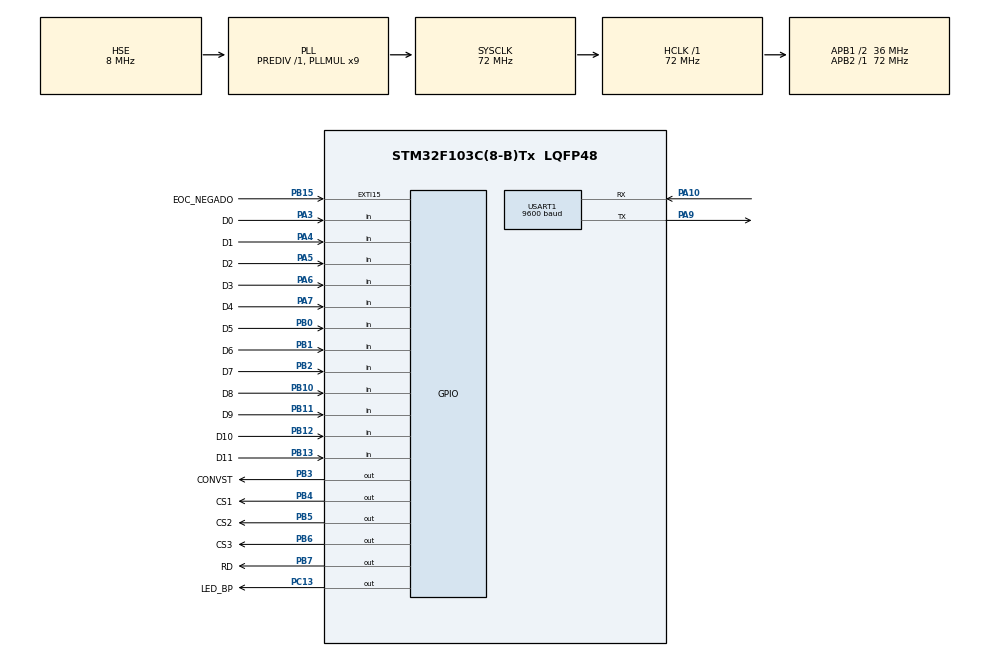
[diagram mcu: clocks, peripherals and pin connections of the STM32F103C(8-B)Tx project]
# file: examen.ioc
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Mcu.Family=STM32F1
Mcu.Name=STM32F103C(8-B)Tx
Mcu.Package=LQFP48
NVIC.PriorityGroup=NVIC_PRIORITYGROUP_4
PA10.Mode=Asynchronous
PA10.Signal=USART1_RX
PA13.Mode=Serial_Wire
PA13.Signal=SYS_JTMS-SWDIO
PA14.Mode=Serial_Wire
PA14.Signal=SYS_JTCK-SWCLK
PA3.GPIO_Label=D0
PA3.Signal=GPIO_Input
PA4.GPIO_Label=D1
PA4.Signal=GPIO_Input
PA5.GPIO_Label=D2
PA5.Signal=GPIO_Input
PA6.GPIO_Label=D3
PA6.Signal=GPIO_Input
PA7.GPIO_Label=D4
PA7.Signal=GPIO_Input
PA9.Mode=Asynchronous
PA9.Signal=USART1_TX
PB0.GPIO_Label=D5
PB0.Signal=GPIO_Input
PB1.GPIO_Label=D6
PB1.Signal=GPIO_Input
PB10.GPIO_Label=D8
PB10.Signal=GPIO_Input
PB11.GPIO_Label=D9
PB11.Signal=GPIO_Input
PB12.GPIO_Label=D10
PB12.Signal=GPIO_Input
PB13.GPIO_Label=D11
PB13.Signal=GPIO_Input
PB15.GPIO_Label=EOC_NEGADO
PB15.GPIO_ModeDefaultEXTI=GPIO_MODE_IT_FALLING
PB15.Signal=GPXTI15
PB2.GPIO_Label=D7
PB2.Signal=GPIO_Input
PB3.GPIO_Label=CONVST
PB3.Signal=GPIO_Output
PB4.GPIO_Label=CS1
PB4.Signal=GPIO_Output
PB5.GPIO_Label=CS2
PB5.Signal=GPIO_Output
PB6.GPIO_Label=CS3
PB6.Signal=GPIO_Output
PB7.GPIO_Label=RD
PB7.Signal=GPIO_Output
PC13-TAMPER-RTC.GPIO_Label=LED_BP
PC13-TAMPER-RTC.Signal=GPIO_Output
PC14-OSC32_IN.Mode=LSE-External-Oscillator
PC14-OSC32_IN.Signal=RCC_OSC32_IN
PC15-OSC32_OUT.Mode=LSE-External-Oscillator
PC15-OSC32_OUT.Signal=RCC_OSC32_OUT
PD0-OSC_IN.Mode=HSE-External-Oscillator
PD0-OSC_IN.Signal=RCC_OSC_IN
PD1-OSC_OUT.Mode=HSE-External-Oscillator
PD1-OSC_OUT.Signal=RCC_OSC_OUT
ProjectManager.HeapSize=0x200
ProjectManager.StackSize=0x400
ProjectManager.TargetToolchain=STM32CubeIDE
RCC.AHBFreq_Value=72000000
RCC.APB1CLKDivider=RCC_HCLK_DIV2
RCC.APB1Freq_Value=36000000
RCC.APB1TimFreq_Value=72000000
RCC.APB2Freq_Value=72000000
RCC.APB2TimFreq_Value=72000000
RCC.HCLKFreq_Value=72000000
RCC.PLLMUL=RCC_PLL_MUL9
RCC.PLLSourceVirtual=RCC_PLLSOURCE_HSE
RCC.SYSCLKFreq_VALUE=72000000
RCC.SYSCLKSource=RCC_SYSCLKSOURCE_PLLCLK
RCC.USBFreq_Value=72000000
USART1.BaudRate=9600
USART1.VirtualMode=VM_ASYNC
board=custom

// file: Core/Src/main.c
/* USER CODE BEGIN Header */
/**
  ******************************************************************************
  * @file           : main.c
  * @brief          : Main program body
  ******************************************************************************
  * @attention
  *
  * <h2><center>&copy; Copyright (c) 2021 STMicroelectronics.
  * All rights reserved.</center></h2>
  *
  * This software component is licensed by ST under BSD 3-Clause license,
  * the "License"; You may not use this file except in compliance with the
  * License. You may obtain a copy of the License at:
  *                        opensource.org/licenses/BSD-3-Clause
  *
  ******************************************************************************
  */
/* USER CODE END Header */
#include "main.h"

/* USER CODE BEGIN Includes */
#include "fsm.h"
#include "user_gpio.h"

/* USER CODE END Includes */

UART_HandleTypeDef huart1;

void SystemClock_Config(void);
static void MX_GPIO_Init(void);
static void MX_USART1_UART_Init(void);

/* USER CODE BEGIN 0 */
void HAL_IncTick(void) {
	uwTick += uwTickFreq;
	fsm_tick();

}

/* USER CODE END 0 */

int main(void)
{

  /* MCU Configuration--------------------------------------------------------*/

  /* Reset of all peripherals, Initializes the Flash interface and the Systick. */
  HAL_Init();

  /* Configure the system clock */
  SystemClock_Config();

  /* Initialize all configured peripherals */
  MX_GPIO_Init();
  MX_USART1_UART_Init();
  /* USER CODE BEGIN 2 */
  user_gpio_init();
  fsm_init();

  /* USER CODE END 2 */

  /* Infinite loop */
  /* USER CODE BEGIN WHILE */
  while (1)
  {
	   fsm_runCycle();
	   __WFI();

    /* USER CODE END WHILE */

  }
}

void SystemClock_Config(void)
{
  RCC_OscInitTypeDef RCC_OscInitStruct = {0};
  RCC_ClkInitTypeDef RCC_ClkInitStruct = {0};

  /** Initializes the RCC Oscillators according to the specified parameters
  * in the RCC_OscInitTypeDef structure.
  */
  RCC_OscInitStruct.OscillatorType = RCC_OSCILLATORTYPE_HSE;
  RCC_OscInitStruct.HSEState = RCC_HSE_ON;
  RCC_OscInitStruct.HSEPredivValue = RCC_HSE_PREDIV_DIV1;
  RCC_OscInitStruct.HSIState = RCC_HSI_ON;
  RCC_OscInitStruct.PLL.PLLState = RCC_PLL_ON;
  RCC_OscInitStruct.PLL.PLLSource = RCC_PLLSOURCE_HSE;
  RCC_OscInitStruct.PLL.PLLMUL = RCC_PLL_MUL9;
  if (HAL_RCC_OscConfig(&RCC_OscInitStruct) != HAL_OK)
  {
    Error_Handler();
  }

  /** Initializes the CPU, AHB and APB buses clocks
  */
  RCC_ClkInitStruct.ClockType = RCC_CLOCKTYPE_HCLK|RCC_CLOCKTYPE_SYSCLK
                              |RCC_CLOCKTYPE_PCLK1|RCC_CLOCKTYPE_PCLK2;
  RCC_ClkInitStruct.SYSCLKSource = RCC_SYSCLKSOURCE_PLLCLK;
  RCC_ClkInitStruct.AHBCLKDivider = RCC_SYSCLK_DIV1;
  RCC_ClkInitStruct.APB1CLKDivider = RCC_HCLK_DIV2;
  RCC_ClkInitStruct.APB2CLKDivider = RCC_HCLK_DIV1;

  if (HAL_RCC_ClockConfig(&RCC_ClkInitStruct, FLASH_LATENCY_2) != HAL_OK)
  {
    Error_Handler();
  }
}

static void MX_USART1_UART_Init(void)
{

  huart1.Instance = USART1;
  huart1.Init.BaudRate = 9600;
  huart1.Init.WordLength = UART_WORDLENGTH_8B;
  huart1.Init.StopBits = UART_STOPBITS_1;
  huart1.Init.Parity = UART_PARITY_NONE;
  huart1.Init.Mode = UART_MODE_TX_RX;
  huart1.Init.HwFlowCtl = UART_HWCONTROL_NONE;
  huart1.Init.OverSampling = UART_OVERSAMPLING_16;
  if (HAL_UART_Init(&huart1) != HAL_OK)
  {
    Error_Handler();
  }

}

static void MX_GPIO_Init(void)
{
  GPIO_InitTypeDef GPIO_InitStruct = {0};

  /* GPIO Ports Clock Enable */
  __HAL_RCC_GPIOC_CLK_ENABLE();
  __HAL_RCC_GPIOD_CLK_ENABLE();
  __HAL_RCC_GPIOA_CLK_ENABLE();
  __HAL_RCC_GPIOB_CLK_ENABLE();

  /*Configure GPIO pin Output Level */
  HAL_GPIO_WritePin(LED_BP_GPIO_Port, LED_BP_Pin, GPIO_PIN_RESET);

  /*Configure GPIO pin Output Level */
  HAL_GPIO_WritePin(GPIOB, CONVST_Pin|CS1_Pin|CS2_Pin|CS3_Pin
                          |RD_Pin, GPIO_PIN_RESET);

  /*Configure GPIO pin : LED_BP_Pin */
  GPIO_InitStruct.Pin = LED_BP_Pin;
  GPIO_InitStruct.Mode = GPIO_MODE_OUTPUT_PP;
  GPIO_InitStruct.Pull = GPIO_NOPULL;
  GPIO_InitStruct.Speed = GPIO_SPEED_FREQ_LOW;
  HAL_GPIO_Init(LED_BP_GPIO_Port, &GPIO_InitStruct);

  /*Configure GPIO pins : D0_Pin D1_Pin D2_Pin D3_Pin
                           D4_Pin */
  GPIO_InitStruct.Pin = D0_Pin|D1_Pin|D2_Pin|D3_Pin
                          |D4_Pin;
  GPIO_InitStruct.Mode = GPIO_MODE_INPUT;
  GPIO_InitStruct.Pull = GPIO_NOPULL;
  HAL_GPIO_Init(GPIOA, &GPIO_InitStruct);

  /*Configure GPIO pins : D5_Pin D6_Pin D7_Pin D8_Pin
                           D9_Pin D10_Pin D11_Pin */
  GPIO_InitStruct.Pin = D5_Pin|D6_Pin|D7_Pin|D8_Pin
                          |D9_Pin|D10_Pin|D11_Pin;
  GPIO_InitStruct.Mode = GPIO_MODE_INPUT;
  GPIO_InitStruct.Pull = GPIO_NOPULL;
  HAL_GPIO_Init(GPIOB, &GPIO_InitStruct);

  /*Configure GPIO pin : EOC_NEGADO_Pin */
  GPIO_InitStruct.Pin = EOC_NEGADO_Pin;
  GPIO_InitStruct.Mode = GPIO_MODE_IT_FALLING;
  GPIO_InitStruct.Pull = GPIO_NOPULL;
  HAL_GPIO_Init(EOC_NEGADO_GPIO_Port, &GPIO_InitStruct);

  /*Configure GPIO pins : CONVST_Pin CS1_Pin CS2_Pin CS3_Pin
                           RD_Pin */
  GPIO_InitStruct.Pin = CONVST_Pin|CS1_Pin|CS2_Pin|CS3_Pin
                          |RD_Pin;
  GPIO_InitStruct.Mode = GPIO_MODE_OUTPUT_PP;
  GPIO_InitStruct.Pull = GPIO_NOPULL;
  GPIO_InitStruct.Speed = GPIO_SPEED_FREQ_LOW;
  HAL_GPIO_Init(GPIOB, &GPIO_InitStruct);

}

void Error_Handler(void)
{
  __disable_irq();
  while (1)
  {
  }
}
